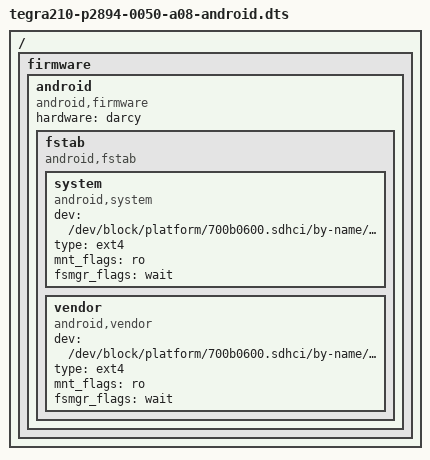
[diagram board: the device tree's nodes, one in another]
// SPDX-License-Identifier: GPL-2.0
/dts-v1/;

#include "tegra210-p2894-0050-a08.dts"

/ {
	firmware {
		android {
			compatible = "android,firmware";
			hardware = "darcy";
			fstab {
				compatible = "android,fstab";
				system {
					compatible = "android,system";
					dev = "/dev/block/platform/700b0600.sdhci/by-name/APP";
					type = "ext4";
					mnt_flags = "ro";
					fsmgr_flags = "wait";
				};
				vendor {
					compatible = "android,vendor";
					dev = "/dev/block/platform/700b0600.sdhci/by-name/vendor";
					type = "ext4";
					mnt_flags = "ro";
					fsmgr_flags = "wait";
				};
			};
		};
	};
};
